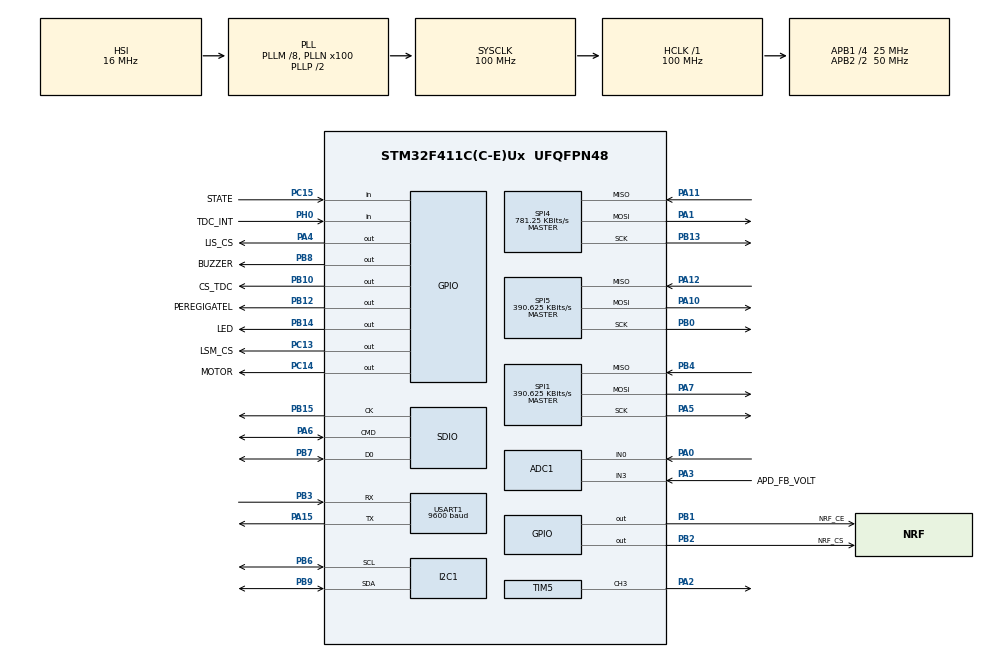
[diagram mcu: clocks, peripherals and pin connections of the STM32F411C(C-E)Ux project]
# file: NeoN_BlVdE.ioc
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ADC1.Channel-0\#ChannelRegularConversion=ADC_CHANNEL_0
ADC1.ClockPrescaler=ADC_CLOCK_SYNC_PCLK_DIV4
ADC1.ContinuousConvMode=DISABLE
ADC1.DMAContinuousRequests=DISABLE
ADC1.DiscontinuousConvMode=DISABLE
ADC1.EOCSelection=ADC_EOC_SINGLE_CONV
ADC1.InjNumberOfConversion=0
ADC1.NbrOfConversion=1
ADC1.NbrOfConversionFlag=1
ADC1.Rank-0\#ChannelRegularConversion=1
ADC1.SamplingTime-0\#ChannelRegularConversion=ADC_SAMPLETIME_480CYCLES
ADC1.master=1
FATFS._MAX_LFN=32
FATFS._MAX_SS=4096
FATFS._USE_LFN=1
Mcu.Family=STM32F4
Mcu.Name=STM32F411C(C-E)Ux
Mcu.Package=UFQFPN48
NVIC.PriorityGroup=NVIC_PRIORITYGROUP_4
NVIC.USART1_IRQn=true\:0\:0\:false\:false\:true\:true\:true
PA0-WKUP.Signal=ADCx_IN0
PA1.Mode=Full_Duplex_Master
PA1.Signal=SPI4_MOSI
PA10.Mode=Full_Duplex_Master
PA10.Signal=SPI5_MOSI
PA11.Mode=Full_Duplex_Master
PA11.Signal=SPI4_MISO
PA12.Mode=Full_Duplex_Master
PA12.Signal=SPI5_MISO
PA13.Mode=Serial_Wire
PA13.Signal=SYS_JTMS-SWDIO
PA14.Mode=Serial_Wire
PA14.Signal=SYS_JTCK-SWCLK
PA15.Mode=Asynchronous
PA15.Signal=USART1_TX
PA2.Signal=S_TIM5_CH3
PA3.GPIO_Label=APD_FB_VOLT
PA3.Signal=ADCx_IN3
PA4.GPIO_Label=LIS_CS
PA4.PinState=GPIO_PIN_SET
PA4.Signal=GPIO_Output
PA5.Mode=Full_Duplex_Master
PA5.Signal=SPI1_SCK
PA6.GPIO_Mode=GPIO_MODE_AF_PP
PA6.GPIO_PuPd=GPIO_NOPULL
PA6.GPIO_Speed_High_Default=GPIO_SPEED_FREQ_VERY_HIGH
PA6.Mode=SD_1_bit
PA6.Signal=SDIO_CMD
PA7.Mode=Full_Duplex_Master
PA7.Signal=SPI1_MOSI
PA8.Signal=SDIO_D1
PA9.Signal=SDIO_D2
PB0.Mode=Full_Duplex_Master
PB0.Signal=SPI5_SCK
PB1.GPIO_Label=NRF_CE
PB1.Signal=GPIO_Output
PB10.GPIO_Label=CS_TDC
PB10.Signal=GPIO_Output
PB12.GPIO_Label=PEREGIGATEL
PB12.Signal=GPIO_Output
PB13.Mode=Full_Duplex_Master
PB13.Signal=SPI4_SCK
PB14.GPIO_Label=LED
PB14.Signal=GPIO_Output
PB15.GPIO_Mode=GPIO_MODE_AF_PP
PB15.GPIO_PuPd=GPIO_NOPULL
PB15.GPIO_Speed_High_Default=GPIO_SPEED_FREQ_VERY_HIGH
PB15.Mode=SD_1_bit
PB15.Signal=SDIO_CK
PB2.GPIO_Label=NRF_CS
PB2.Signal=GPIO_Output
PB3.Mode=Asynchronous
PB3.Signal=USART1_RX
PB4.Mode=Full_Duplex_Master
PB4.Signal=SPI1_MISO
PB5.Signal=SDIO_D3
PB6.Mode=I2C
PB6.Signal=I2C1_SCL
PB7.Mode=SD_1_bit
PB7.Signal=SDIO_D0
PB8.GPIO_Label=BUZZER
PB8.Signal=GPIO_Output
PB9.Mode=I2C
PB9.Signal=I2C1_SDA
PC13-ANTI_TAMP.GPIO_Label=LSM_CS
PC13-ANTI_TAMP.PinState=GPIO_PIN_SET
PC13-ANTI_TAMP.Signal=GPIO_Output
PC14-OSC32_IN.GPIO_Label=MOTOR
PC14-OSC32_IN.Signal=GPIO_Output
PC15-OSC32_OUT.GPIO_Label=STATE
PC15-OSC32_OUT.Signal=GPIO_Input
PH0\ -\ OSC_IN.GPIO_Label=TDC_INT
PH0\ -\ OSC_IN.Signal=GPIO_Input
ProjectManager.HeapSize=0x200
ProjectManager.StackSize=0x400
ProjectManager.TargetToolchain=STM32CubeIDE
RCC.48MHZClocksFreq_Value=28571428.57142857
RCC.AHBFreq_Value=100000000
RCC.APB1CLKDivider=RCC_HCLK_DIV4
RCC.APB1Freq_Value=25000000
RCC.APB1TimFreq_Value=50000000
RCC.APB2CLKDivider=RCC_HCLK_DIV2
RCC.APB2Freq_Value=50000000
RCC.APB2TimFreq_Value=100000000
RCC.CortexFreq_Value=100000000
RCC.HCLKFreq_Value=100000000
RCC.HSE_VALUE=25000000
RCC.HSI_VALUE=16000000
RCC.LSE_VALUE=32768
RCC.PLLM=8
RCC.PLLN=100
RCC.PLLQ=7
RCC.SYSCLKFreq_VALUE=100000000
RCC.SYSCLKSource=RCC_SYSCLKSOURCE_PLLCLK
RCC.VCOOutputFreq_Value=200000000
SDIO.ClockDiv=3
SH.ADCx_IN0.0=ADC1_IN0,IN0
SH.ADCx_IN3.0=ADC1_IN3,IN3
SH.S_TIM5_CH3.0=TIM5_CH3,PWM Generation3 CH3
SPI1.BaudRatePrescaler=SPI_BAUDRATEPRESCALER_128
SPI1.CLKPhase=SPI_PHASE_2EDGE
SPI1.CLKPolarity=SPI_POLARITY_HIGH
SPI1.CalculateBaudRate=390.625 KBits/s
SPI1.Direction=SPI_DIRECTION_2LINES
SPI1.Mode=SPI_MODE_MASTER
SPI1.VirtualType=VM_MASTER
SPI4.BaudRatePrescaler=SPI_BAUDRATEPRESCALER_64
SPI4.CLKPhase=SPI_PHASE_2EDGE
SPI4.CLKPolarity=SPI_POLARITY_LOW
SPI4.CalculateBaudRate=781.25 KBits/s
SPI4.Direction=SPI_DIRECTION_2LINES
SPI4.Mode=SPI_MODE_MASTER
SPI4.VirtualType=VM_MASTER
SPI5.BaudRatePrescaler=SPI_BAUDRATEPRESCALER_128
SPI5.CalculateBaudRate=390.625 KBits/s
SPI5.Direction=SPI_DIRECTION_2LINES
SPI5.Mode=SPI_MODE_MASTER
SPI5.VirtualType=VM_MASTER
TIM5.Channel-PWM\ Generation3\ CH3=TIM_CHANNEL_3
TIM5.Period=999
TIM5.Prescaler=1
TIM5.Pulse-PWM\ Generation3\ CH3=125
USART1.BaudRate=9600
USART1.VirtualMode=VM_ASYNC
VP_FATFS_VS_SDIO.Mode=SDIO
board=custom

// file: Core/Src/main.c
/* USER CODE BEGIN Header */
/**
  ******************************************************************************
  * @file           : main.c
  * @brief          : Main program body
  ******************************************************************************
  * @attention
  *
  * Copyright (c) 2023 STMicroelectronics.
  * All rights reserved.
  *
  * This software is licensed under terms that can be found in the LICENSE file
  * in the root directory of this software component.
  * If no LICENSE file comes with this software, it is provided AS-IS.
  *
  ******************************************************************************
  */
/* USER CODE END Header */
#include "main.h"
#include "fatfs.h"

ADC_HandleTypeDef hadc1;

I2C_HandleTypeDef hi2c1;

SD_HandleTypeDef hsd;

SPI_HandleTypeDef hspi1;
SPI_HandleTypeDef hspi4;
SPI_HandleTypeDef hspi5;

TIM_HandleTypeDef htim5;

UART_HandleTypeDef huart1;

void SystemClock_Config(void);
static void MX_GPIO_Init(void);
static void MX_SPI5_Init(void);
static void MX_I2C1_Init(void);
static void MX_SDIO_SD_Init(void);
static void MX_SPI1_Init(void);
static void MX_SPI4_Init(void);
static void MX_USART1_UART_Init(void);
static void MX_ADC1_Init(void);
static void MX_TIM5_Init(void);
/* USER CODE BEGIN PFP */

int app_main();
/* USER CODE END PFP */

int main(void)
{

  /* MCU Configuration--------------------------------------------------------*/

  /* Reset of all peripherals, Initializes the Flash interface and the Systick. */

   HAL_Init();

  /* Configure the system clock */
  SystemClock_Config();

  /* Initialize all configured peripherals */
  MX_GPIO_Init();
  MX_SPI5_Init();
  MX_I2C1_Init();
  MX_SDIO_SD_Init();
  MX_SPI1_Init();
  MX_SPI4_Init();
  MX_USART1_UART_Init();
  MX_FATFS_Init();
  MX_ADC1_Init();
  MX_TIM5_Init();
  /* USER CODE BEGIN 2 */
  //HAL_TIM_Base_Start_IT(&htim1);//////////////////////////////////////////////////////////////////////////////////////////////////////////
  HAL_TIM_PWM_Start(&htim5, TIM_CHANNEL_3);
  app_main();
  /* USER CODE END 2 */

  /* Infinite loop */
  while (1)
  {

  }
}

void SystemClock_Config(void)
{
  RCC_OscInitTypeDef RCC_OscInitStruct = {0};
  RCC_ClkInitTypeDef RCC_ClkInitStruct = {0};

  /** Configure the main internal regulator output voltage
  */
  __HAL_RCC_PWR_CLK_ENABLE();
  __HAL_PWR_VOLTAGESCALING_CONFIG(PWR_REGULATOR_VOLTAGE_SCALE1);
  /** Initializes the RCC Oscillators according to the specified parameters
  * in the RCC_OscInitTypeDef structure.
  */
  RCC_OscInitStruct.OscillatorType = RCC_OSCILLATORTYPE_HSI;
  RCC_OscInitStruct.HSIState = RCC_HSI_ON;
  RCC_OscInitStruct.HSICalibrationValue = RCC_HSICALIBRATION_DEFAULT;
  RCC_OscInitStruct.PLL.PLLState = RCC_PLL_ON;
  RCC_OscInitStruct.PLL.PLLSource = RCC_PLLSOURCE_HSI;
  RCC_OscInitStruct.PLL.PLLM = 8;
  RCC_OscInitStruct.PLL.PLLN = 100;
  RCC_OscInitStruct.PLL.PLLP = RCC_PLLP_DIV2;
  RCC_OscInitStruct.PLL.PLLQ = 7;
  if (HAL_RCC_OscConfig(&RCC_OscInitStruct) != HAL_OK)
  {
    Error_Handler();
  }
  /** Initializes the CPU, AHB and APB buses clocks
  */
  RCC_ClkInitStruct.ClockType = RCC_CLOCKTYPE_HCLK|RCC_CLOCKTYPE_SYSCLK
                              |RCC_CLOCKTYPE_PCLK1|RCC_CLOCKTYPE_PCLK2;
  RCC_ClkInitStruct.SYSCLKSource = RCC_SYSCLKSOURCE_PLLCLK;
  RCC_ClkInitStruct.AHBCLKDivider = RCC_SYSCLK_DIV1;
  RCC_ClkInitStruct.APB1CLKDivider = RCC_HCLK_DIV4;
  RCC_ClkInitStruct.APB2CLKDivider = RCC_HCLK_DIV2;

  if (HAL_RCC_ClockConfig(&RCC_ClkInitStruct, FLASH_LATENCY_3) != HAL_OK)
  {
    Error_Handler();
  }
}

static void MX_ADC1_Init(void)
{

  ADC_ChannelConfTypeDef sConfig = {0};

  /** Configure the global features of the ADC (Clock, Resolution, Data Alignment and number of conversion)
  */
  hadc1.Instance = ADC1;
  hadc1.Init.ClockPrescaler = ADC_CLOCK_SYNC_PCLK_DIV4;
  hadc1.Init.Resolution = ADC_RESOLUTION_12B;
  hadc1.Init.ScanConvMode = DISABLE;
  hadc1.Init.ContinuousConvMode = DISABLE;
  hadc1.Init.DiscontinuousConvMode = DISABLE;
  hadc1.Init.ExternalTrigConvEdge = ADC_EXTERNALTRIGCONVEDGE_NONE;
  hadc1.Init.ExternalTrigConv = ADC_SOFTWARE_START;
  hadc1.Init.DataAlign = ADC_DATAALIGN_RIGHT;
  hadc1.Init.NbrOfConversion = 1;
  hadc1.Init.DMAContinuousRequests = DISABLE;
  hadc1.Init.EOCSelection = ADC_EOC_SINGLE_CONV;
  if (HAL_ADC_Init(&hadc1) != HAL_OK)
  {
    Error_Handler();
  }
  /** Configure for the selected ADC regular channel its corresponding rank in the sequencer and its sample time.
  */
  sConfig.Channel = ADC_CHANNEL_0;
  sConfig.Rank = 1;
  sConfig.SamplingTime = ADC_SAMPLETIME_480CYCLES;
  if (HAL_ADC_ConfigChannel(&hadc1, &sConfig) != HAL_OK)
  {
    Error_Handler();
  }

}

static void MX_I2C1_Init(void)
{

  hi2c1.Instance = I2C1;
  hi2c1.Init.ClockSpeed = 100000;
  hi2c1.Init.DutyCycle = I2C_DUTYCYCLE_2;
  hi2c1.Init.OwnAddress1 = 0;
  hi2c1.Init.AddressingMode = I2C_ADDRESSINGMODE_7BIT;
  hi2c1.Init.DualAddressMode = I2C_DUALADDRESS_DISABLE;
  hi2c1.Init.OwnAddress2 = 0;
  hi2c1.Init.GeneralCallMode = I2C_GENERALCALL_DISABLE;
  hi2c1.Init.NoStretchMode = I2C_NOSTRETCH_DISABLE;
  if (HAL_I2C_Init(&hi2c1) != HAL_OK)
  {
    Error_Handler();
  }

}

static void MX_SDIO_SD_Init(void)
{

  hsd.Instance = SDIO;
  hsd.Init.ClockEdge = SDIO_CLOCK_EDGE_RISING;
  hsd.Init.ClockBypass = SDIO_CLOCK_BYPASS_DISABLE;
  hsd.Init.ClockPowerSave = SDIO_CLOCK_POWER_SAVE_DISABLE;
  hsd.Init.BusWide = SDIO_BUS_WIDE_1B;
  hsd.Init.HardwareFlowControl = SDIO_HARDWARE_FLOW_CONTROL_DISABLE;
  hsd.Init.ClockDiv = 3;
  /* USER CODE BEGIN SDIO_Init 2 */
  hsd.Init.BusWide = SDIO_BUS_WIDE_1B;
  /* USER CODE END SDIO_Init 2 */

}

static void MX_SPI1_Init(void)
{

  /* SPI1 parameter configuration*/
  hspi1.Instance = SPI1;
  hspi1.Init.Mode = SPI_MODE_MASTER;
  hspi1.Init.Direction = SPI_DIRECTION_2LINES;
  hspi1.Init.DataSize = SPI_DATASIZE_8BIT;
  hspi1.Init.CLKPolarity = SPI_POLARITY_HIGH;
  hspi1.Init.CLKPhase = SPI_PHASE_2EDGE;
  hspi1.Init.NSS = SPI_NSS_SOFT;
  hspi1.Init.BaudRatePrescaler = SPI_BAUDRATEPRESCALER_128;
  hspi1.Init.FirstBit = SPI_FIRSTBIT_MSB;
  hspi1.Init.TIMode = SPI_TIMODE_DISABLE;
  hspi1.Init.CRCCalculation = SPI_CRCCALCULATION_DISABLE;
  hspi1.Init.CRCPolynomial = 10;
  if (HAL_SPI_Init(&hspi1) != HAL_OK)
  {
    Error_Handler();
  }

}

static void MX_SPI4_Init(void)
{

  /* SPI4 parameter configuration*/
  hspi4.Instance = SPI4;
  hspi4.Init.Mode = SPI_MODE_MASTER;
  hspi4.Init.Direction = SPI_DIRECTION_2LINES;
  hspi4.Init.DataSize = SPI_DATASIZE_8BIT;
  hspi4.Init.CLKPolarity = SPI_POLARITY_LOW;
  hspi4.Init.CLKPhase = SPI_PHASE_2EDGE;
  hspi4.Init.NSS = SPI_NSS_SOFT;
  hspi4.Init.BaudRatePrescaler = SPI_BAUDRATEPRESCALER_64;
  hspi4.Init.FirstBit = SPI_FIRSTBIT_MSB;
  hspi4.Init.TIMode = SPI_TIMODE_DISABLE;
  hspi4.Init.CRCCalculation = SPI_CRCCALCULATION_DISABLE;
  hspi4.Init.CRCPolynomial = 10;
  if (HAL_SPI_Init(&hspi4) != HAL_OK)
  {
    Error_Handler();
  }

}

static void MX_SPI5_Init(void)
{

  /* SPI5 parameter configuration*/
  hspi5.Instance = SPI5;
  hspi5.Init.Mode = SPI_MODE_MASTER;
  hspi5.Init.Direction = SPI_DIRECTION_2LINES;
  hspi5.Init.DataSize = SPI_DATASIZE_8BIT;
  hspi5.Init.CLKPolarity = SPI_POLARITY_LOW;
  hspi5.Init.CLKPhase = SPI_PHASE_1EDGE;
  hspi5.Init.NSS = SPI_NSS_SOFT;
  hspi5.Init.BaudRatePrescaler = SPI_BAUDRATEPRESCALER_128;
  hspi5.Init.FirstBit = SPI_FIRSTBIT_MSB;
  hspi5.Init.TIMode = SPI_TIMODE_DISABLE;
  hspi5.Init.CRCCalculation = SPI_CRCCALCULATION_DISABLE;
  hspi5.Init.CRCPolynomial = 10;
  if (HAL_SPI_Init(&hspi5) != HAL_OK)
  {
    Error_Handler();
  }

}

static void MX_TIM5_Init(void)
{

  TIM_MasterConfigTypeDef sMasterConfig = {0};
  TIM_OC_InitTypeDef sConfigOC = {0};

  htim5.Instance = TIM5;
  htim5.Init.Prescaler = 1;
  htim5.Init.CounterMode = TIM_COUNTERMODE_UP;
  htim5.Init.Period = 999;
  htim5.Init.ClockDivision = TIM_CLOCKDIVISION_DIV1;
  htim5.Init.AutoReloadPreload = TIM_AUTORELOAD_PRELOAD_DISABLE;
  if (HAL_TIM_PWM_Init(&htim5) != HAL_OK)
  {
    Error_Handler();
  }
  sMasterConfig.MasterOutputTrigger = TIM_TRGO_RESET;
  sMasterConfig.MasterSlaveMode = TIM_MASTERSLAVEMODE_DISABLE;
  if (HAL_TIMEx_MasterConfigSynchronization(&htim5, &sMasterConfig) != HAL_OK)
  {
    Error_Handler();
  }
  sConfigOC.OCMode = TIM_OCMODE_PWM1;
  sConfigOC.Pulse = 125;
  sConfigOC.OCPolarity = TIM_OCPOLARITY_HIGH;
  sConfigOC.OCFastMode = TIM_OCFAST_DISABLE;
  if (HAL_TIM_PWM_ConfigChannel(&htim5, &sConfigOC, TIM_CHANNEL_3) != HAL_OK)
  {
    Error_Handler();
  }
  HAL_TIM_MspPostInit(&htim5);

}

static void MX_USART1_UART_Init(void)
{

  huart1.Instance = USART1;
  huart1.Init.BaudRate = 9600;
  huart1.Init.WordLength = UART_WORDLENGTH_8B;
  huart1.Init.StopBits = UART_STOPBITS_1;
  huart1.Init.Parity = UART_PARITY_NONE;
  huart1.Init.Mode = UART_MODE_TX_RX;
  huart1.Init.HwFlowCtl = UART_HWCONTROL_NONE;
  huart1.Init.OverSampling = UART_OVERSAMPLING_16;
  if (HAL_UART_Init(&huart1) != HAL_OK)
  {
    Error_Handler();
  }

}

static void MX_GPIO_Init(void)
{
  GPIO_InitTypeDef GPIO_InitStruct = {0};

  /* GPIO Ports Clock Enable */
  __HAL_RCC_GPIOC_CLK_ENABLE();
  __HAL_RCC_GPIOH_CLK_ENABLE();
  __HAL_RCC_GPIOA_CLK_ENABLE();
  __HAL_RCC_GPIOB_CLK_ENABLE();

  /*Configure GPIO pin Output Level */
  HAL_GPIO_WritePin(LSM_CS_GPIO_Port, LSM_CS_Pin, GPIO_PIN_SET);

  /*Configure GPIO pin Output Level */
  HAL_GPIO_WritePin(MOTOR_GPIO_Port, MOTOR_Pin, GPIO_PIN_RESET);

  /*Configure GPIO pin Output Level */
  HAL_GPIO_WritePin(LIS_CS_GPIO_Port, LIS_CS_Pin, GPIO_PIN_SET);

  /*Configure GPIO pin Output Level */
  HAL_GPIO_WritePin(GPIOB, NRF_CE_Pin|NRF_CS_Pin|CS_TDC_Pin|PEREGIGATEL_Pin
                          |LED_Pin|BUZZER_Pin, GPIO_PIN_RESET);

  /*Configure GPIO pins : LSM_CS_Pin MOTOR_Pin */
  GPIO_InitStruct.Pin = LSM_CS_Pin|MOTOR_Pin;
  GPIO_InitStruct.Mode = GPIO_MODE_OUTPUT_PP;
  GPIO_InitStruct.Pull = GPIO_NOPULL;
  GPIO_InitStruct.Speed = GPIO_SPEED_FREQ_LOW;
  HAL_GPIO_Init(GPIOC, &GPIO_InitStruct);

  /*Configure GPIO pin : STATE_Pin */
  GPIO_InitStruct.Pin = STATE_Pin;
  GPIO_InitStruct.Mode = GPIO_MODE_INPUT;
  GPIO_InitStruct.Pull = GPIO_NOPULL;
  HAL_GPIO_Init(STATE_GPIO_Port, &GPIO_InitStruct);

  /*Configure GPIO pin : TDC_INT_Pin */
  GPIO_InitStruct.Pin = TDC_INT_Pin;
  GPIO_InitStruct.Mode = GPIO_MODE_INPUT;
  GPIO_InitStruct.Pull = GPIO_NOPULL;
  HAL_GPIO_Init(TDC_INT_GPIO_Port, &GPIO_InitStruct);

  /*Configure GPIO pin : LIS_CS_Pin */
  GPIO_InitStruct.Pin = LIS_CS_Pin;
  GPIO_InitStruct.Mode = GPIO_MODE_OUTPUT_PP;
  GPIO_InitStruct.Pull = GPIO_NOPULL;
  GPIO_InitStruct.Speed = GPIO_SPEED_FREQ_LOW;
  HAL_GPIO_Init(LIS_CS_GPIO_Port, &GPIO_InitStruct);

  /*Configure GPIO pins : NRF_CE_Pin NRF_CS_Pin CS_TDC_Pin PEREGIGATEL_Pin
                           LED_Pin BUZZER_Pin */
  GPIO_InitStruct.Pin = NRF_CE_Pin|NRF_CS_Pin|CS_TDC_Pin|PEREGIGATEL_Pin
                          |LED_Pin|BUZZER_Pin;
  GPIO_InitStruct.Mode = GPIO_MODE_OUTPUT_PP;
  GPIO_InitStruct.Pull = GPIO_NOPULL;
  GPIO_InitStruct.Speed = GPIO_SPEED_FREQ_LOW;
  HAL_GPIO_Init(GPIOB, &GPIO_InitStruct);

}

void Error_Handler(void)
{
  __disable_irq();
  while (1)
  {
  }
}
